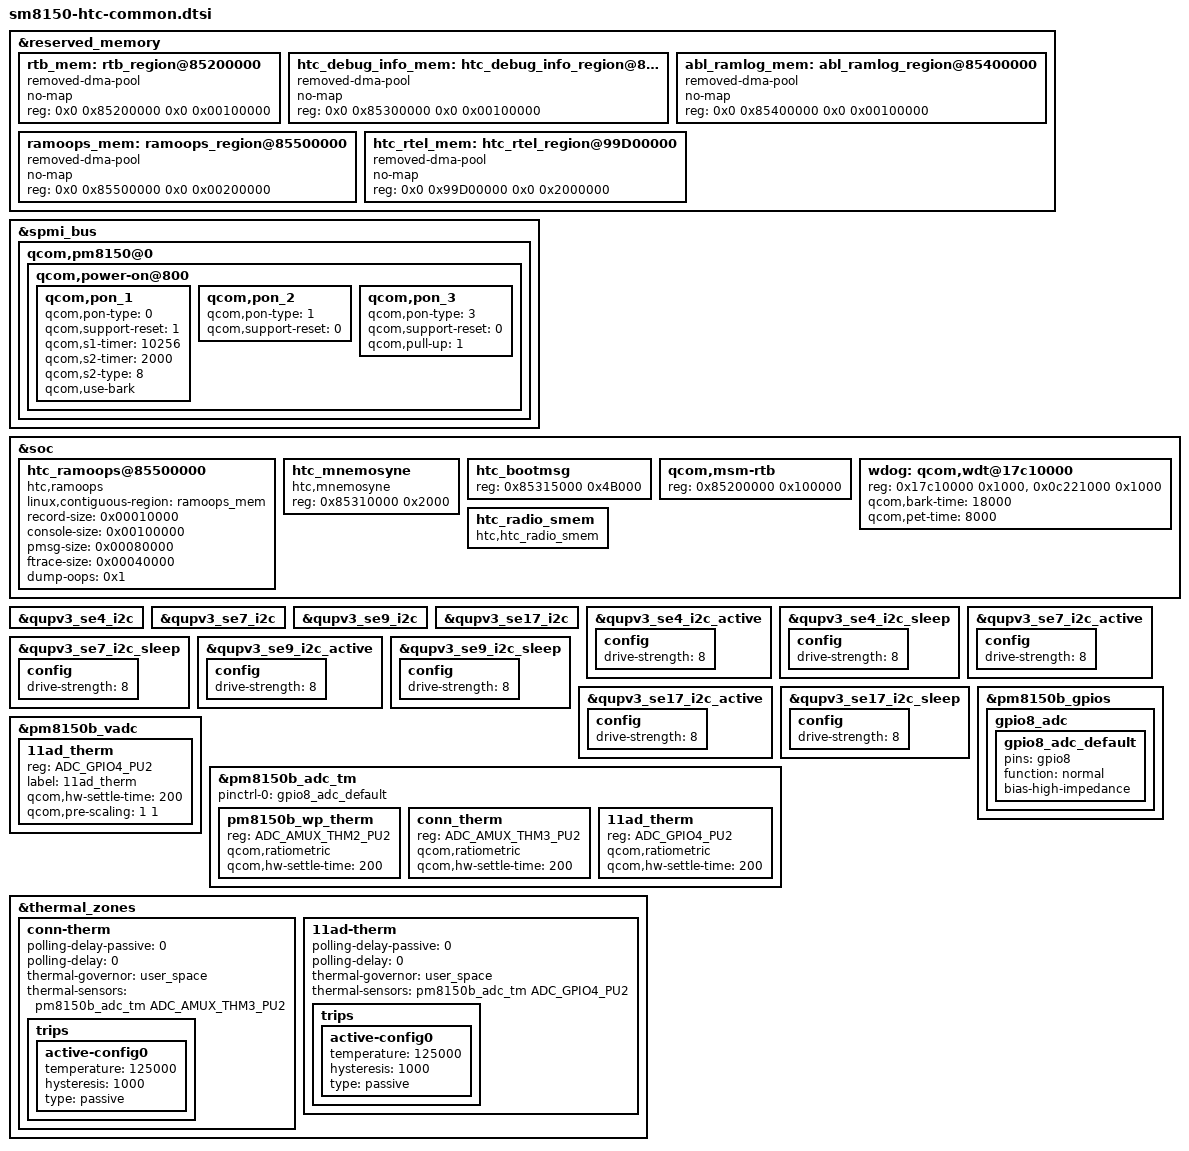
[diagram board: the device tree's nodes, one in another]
/*
 * sm8150-htc-common: common configs of sm8150 HTC projects
 */

&reserved_memory {
	rtb_mem: rtb_region@85200000 {
		compatible = "removed-dma-pool";
		no-map;
		reg = <0x0 0x85200000 0x0 0x00100000>;
	};

	htc_debug_info_mem: htc_debug_info_region@85300000 {
		compatible = "removed-dma-pool";
		no-map;
		reg = <0x0 0x85300000 0x0 0x00100000>;
	};

	abl_ramlog_mem: abl_ramlog_region@85400000 {
		compatible = "removed-dma-pool";
		no-map;
		reg = <0x0 0x85400000 0x0 0x00100000>;
	};

	ramoops_mem: ramoops_region@85500000 {
		compatible = "removed-dma-pool";
		no-map;
		reg = <0x0 0x85500000 0x0 0x00200000>;
	};

	/* SM LOG */
	htc_rtel_mem: htc_rtel_region@99D00000 {
		compatible = "removed-dma-pool";
		no-map;
		reg = <0x0 0x99D00000 0x0 0x2000000>; /* 32 MB */
	};
};

&spmi_bus {
	qcom,pm8150@0 {
		qcom,power-on@800 {
			qcom,pon_1 {
				qcom,pon-type = <0>;
				qcom,support-reset = <1>;
				qcom,s1-timer = <10256>;
				qcom,s2-timer = <2000>;
				qcom,s2-type = <8>;
				qcom,use-bark;
			};
			qcom,pon_2 {
				qcom,pon-type = <1>;
				qcom,support-reset = <0>;
			};
			qcom,pon_3 {
				qcom,pon-type = <3>;
				qcom,support-reset = <0>;
				qcom,pull-up = <1>;
			};
		};
	};
};

&soc {
	/* Kernel_BSP */
	htc_ramoops@85500000 {
		compatible = "htc,ramoops";
		linux,contiguous-region = <&ramoops_mem>;
		record-size = <0x00010000>;  /*  128 KB */
		console-size = <0x00100000>; /* 1024 KB */
		pmsg-size = <0x00080000>;    /*  512 KB */
		ftrace-size = <0x00040000>;  /*  256 KB */
		dump-oops = <0x1>;
	};
	htc_mnemosyne {
		compatible = "htc,mnemosyne";
		reg = <0x85310000 0x2000>;
		reg-names = "htc_mnemosyne_res";
    };
	htc_bootmsg {
		reg = <0x85315000 0x4B000>; /*0x85315000 ~ 0x85360000 300 KB*/
		reg-names = "bootmsg_res";
	};
	qcom,msm-rtb {
		reg = <0x85200000 0x100000>;
		reg-names = "msm_rtb_res";
	};
	wdog: qcom,wdt@17c10000{
		reg = <0x17c10000 0x1000>,
		      <0x0c221000 0x1000>;
		reg-names = "wdt-base",
			    "mpm-clock-base";
		qcom,bark-time = <18000>;
		qcom,pet-time = <8000>;
	};

    /* Modem_BSP */
    htc_radio_smem {
    compatible = "htc,htc_radio_smem";
    };
};

&qupv3_se4_i2c {
	status = "okay";
};

&qupv3_se7_i2c {
	status = "okay";
};

&qupv3_se9_i2c {
	status = "okay";
	/delete-node/ nq@28;
};

&qupv3_se17_i2c {
	status = "okay";
};


&qupv3_se4_i2c_active {
	config {
		drive-strength = <8>;
	};
};
&qupv3_se4_i2c_sleep {
	config {
		drive-strength = <8>;
	};
};

&qupv3_se7_i2c_active {
	config {
		drive-strength = <8>;
	};
};
&qupv3_se7_i2c_sleep {
	config {
		drive-strength = <8>;
	};
};

&qupv3_se9_i2c_active {
	config {
		drive-strength = <8>;
	};
};
&qupv3_se9_i2c_sleep {
	config {
		drive-strength = <8>;
	};
};

&qupv3_se17_i2c_active {
	config {
		drive-strength = <8>;
	};
};
&qupv3_se17_i2c_sleep {
	config {
		drive-strength = <8>;
	};
};

&pm8150b_gpios {
	gpio8_adc {
		gpio8_adc_default: gpio8_adc_default {
			pins = "gpio8";
			function = "normal";
			bias-high-impedance;
		};
	};
};

&pm8150b_vadc {
       11ad_therm {
               reg = <ADC_GPIO4_PU2>;
               label = "11ad_therm";
               qcom,hw-settle-time = <200>;
               qcom,pre-scaling = <1 1>;
       };
};

&pm8150b_adc_tm {
	pinctrl-names = "default";
	pinctrl-0 = <&gpio8_adc_default>;

	pm8150b_wp_therm {
		reg = <ADC_AMUX_THM2_PU2>;
		qcom,ratiometric;
		qcom,hw-settle-time = <200>;
	};

	conn_therm {
		reg = <ADC_AMUX_THM3_PU2>;
		qcom,ratiometric;
		qcom,hw-settle-time = <200>;
	};

	11ad_therm {
	        reg = <ADC_GPIO4_PU2>;
		qcom,ratiometric;
	        qcom,hw-settle-time = <200>;
	};
};

&thermal_zones {
	conn-therm {
		polling-delay-passive = <0>;
		polling-delay = <0>;
		thermal-governor = "user_space";
		thermal-sensors = <&pm8150b_adc_tm ADC_AMUX_THM3_PU2>;
		trips {
			active-config0 {
				temperature = <125000>;
				hysteresis = <1000>;
				type = "passive";
			};
		};
	};

	11ad-therm {
	        polling-delay-passive = <0>;
	        polling-delay = <0>;
	        thermal-governor = "user_space";
	        thermal-sensors = <&pm8150b_adc_tm ADC_GPIO4_PU2>;
	        trips {
	                active-config0 {
	                        temperature = <125000>;
	                        hysteresis = <1000>;
	                        type = "passive";
	                };
	        };
	};
};

